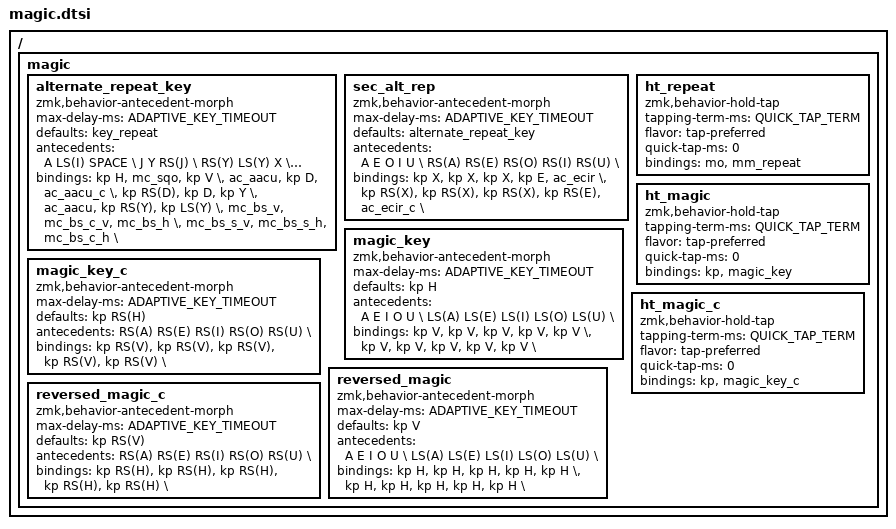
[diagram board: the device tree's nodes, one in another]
/*
*
* Copyright (c) 2022 Rafael Romão
* SPDX-License-Identifier: MIT
*
*/

/ {
    magic {
        
        // ******************** REPEAT KEY ******************** //

        MACRO_TAP(mc_bs_h, &kp BACKSPACE &kp H)
        MACRO_TAP(mc_bs_v, &kp BACKSPACE &kp V)
        MACRO_TAP(mc_bs_c_h, &kp BACKSPACE &kp RS(H))
        MACRO_TAP(mc_bs_s_h, &kp BACKSPACE &kp LS(H))
        MACRO_TAP(mc_bs_c_v, &kp BACKSPACE &kp RS(V))
        MACRO_TAP(mc_bs_s_v, &kp BACKSPACE &kp LS(V))
        
        alternate_repeat_key: alternate_repeat_key {
            compatible = "zmk,behavior-antecedent-morph";
            #binding-cells = <0>;
            max-delay-ms = <ADAPTIVE_KEY_TIMEOUT>;
            defaults = <&key_repeat>;
            antecedents = <
                            A            LS(I)        SPACE       \
                            J            Y            RS(J)       \
                            RS(Y)        LS(Y)        X           \
                            LS(J)        RS(X)        LS(X)       \
                            H            RS(H)        V           \
                            LS(V)        LS(H)        RS(V)       \
                           >;                                                                                      
            bindings =    <                                                                                        
                            &kp H        &mc_sqo      &kp V       \
                            &ac_aacu     &kp D        &ac_aacu_c  \
                            &kp RS(D)    &kp D        &kp Y       \
                            &ac_aacu     &kp RS(Y)    &kp LS(Y)   \
                            &mc_bs_v     &mc_bs_c_v   &mc_bs_h    \
                            &mc_bs_s_v   &mc_bs_s_h   &mc_bs_c_h  \
                           >;
        };

        sec_alt_rep: sec_alt_rep {
            compatible = "zmk,behavior-antecedent-morph";
            #binding-cells = <0>;
            max-delay-ms = <ADAPTIVE_KEY_TIMEOUT>;
            defaults = <&alternate_repeat_key>;
            antecedents = <
                            A            E           O            I            U           \
                            RS(A)        RS(E)       RS(O)        RS(I)        RS(U)       \
                           >;                                                              
            bindings =    <                                                                
                            &kp X        &kp X       &kp X        &kp E        &ac_ecir    \
                            &kp RS(X)    &kp RS(X)   &kp RS(X)    &kp RS(E)    &ac_ecir_c  \
                           >;
        };

        ht_repeat: ht_repeat {
            compatible = "zmk,behavior-hold-tap";
            #binding-cells = <2>;
            tapping-term-ms = <QUICK_TAP_TERM>;
            flavor = "tap-preferred";
            quick-tap-ms = <0>;
            bindings = <&mo>, <&mm_repeat>;
        };

        // ******************** MAGIC KEY ******************** //

        magic_key: magic_key {
            compatible = "zmk,behavior-antecedent-morph";
            #binding-cells = <0>;
            max-delay-ms = <ADAPTIVE_KEY_TIMEOUT>;
            defaults = <&kp H>;
            antecedents = <
                           A             E             I             O             U               \
                           LS(A)         LS(E)         LS(I)         LS(O)         LS(U)           \
                           >;
            bindings =    <
                           &kp V         &kp V         &kp V         &kp V         &kp V           \
                           &kp V         &kp V         &kp V         &kp V         &kp V           \
                           >; 
        };

        magic_key_c: magic_key_c {
            compatible = "zmk,behavior-antecedent-morph";
            #binding-cells = <0>;
            max-delay-ms = <ADAPTIVE_KEY_TIMEOUT>;
            defaults = <&kp RS(H)>;
            antecedents = <
                           RS(A)         RS(E)         RS(I)         RS(O)         RS(U)           \
                           >;
            bindings =    <
                           &kp RS(V)     &kp RS(V)     &kp RS(V)     &kp RS(V)     &kp RS(V)       \
                           >;
        };

        ht_magic: ht_magic {
            compatible = "zmk,behavior-hold-tap";
            #binding-cells = <2>;
            tapping-term-ms = <QUICK_TAP_TERM>;
            flavor = "tap-preferred";
            quick-tap-ms = <0>;
            bindings = <&kp>, <&magic_key>;
        };

        ht_magic_c: ht_magic_c {
            compatible = "zmk,behavior-hold-tap";
            #binding-cells = <2>;
            tapping-term-ms = <QUICK_TAP_TERM>;
            flavor = "tap-preferred";
            quick-tap-ms = <0>;
            bindings = <&kp>, <&magic_key_c>;
        };

        // ******************** REVERSED MAGIC KEY ******************** //

        reversed_magic: reversed_magic {
            compatible = "zmk,behavior-antecedent-morph";
            #binding-cells = <0>;
            max-delay-ms = <ADAPTIVE_KEY_TIMEOUT>;
            defaults = <&kp V>;
            antecedents = <
                           A             E             I             O             U           \
                           LS(A)         LS(E)         LS(I)         LS(O)         LS(U)       \
                           >;
            bindings =    <
                           &kp H         &kp H         &kp H         &kp H         &kp H       \
                           &kp H         &kp H         &kp H         &kp H         &kp H       \
                           >;
        };

        reversed_magic_c: reversed_magic_c {
            compatible = "zmk,behavior-antecedent-morph";
            #binding-cells = <0>;
            max-delay-ms = <ADAPTIVE_KEY_TIMEOUT>;
            defaults = <&kp RS(V)>;
            antecedents = <
                           RS(A)         RS(E)         RS(I)         RS(O)         RS(U)       \
                          >;
            bindings =    <
                           &kp RS(H)     &kp RS(H)     &kp RS(H)     &kp RS(H)     &kp RS(H)   \
                          >;
        };

    };
};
